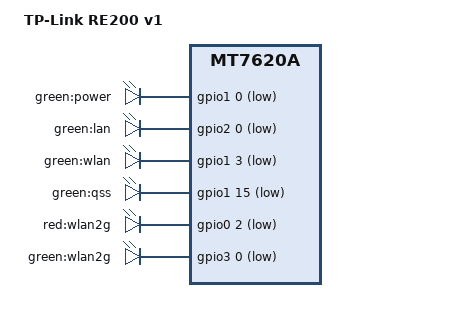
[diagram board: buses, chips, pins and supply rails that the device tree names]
// SPDX-License-Identifier: GPL-2.0-or-later OR MIT

#include "mt7620a_tplink_re2x0-v1.dtsi"

/ {
	compatible = "tplink,re200-v1", "ralink,mt7620a-soc";
	model = "TP-Link RE200 v1";

	aliases {
		led-boot = &led_power;
		led-failsafe = &led_power;
		led-running = &led_power;
		led-upgrade = &led_power;
	};

	leds {
		compatible = "gpio-leds";

		led_power: power {
			label = "green:power";
			gpios = <&gpio1 0 GPIO_ACTIVE_LOW>;
		};

		lan {
			label = "green:lan";
			gpios = <&gpio2 0 GPIO_ACTIVE_LOW>;
		};

		wlan {
			label = "green:wlan";
			gpios = <&gpio1 3 GPIO_ACTIVE_LOW>;
		};

		qss {
			label = "green:qss";
			gpios = <&gpio1 15 GPIO_ACTIVE_LOW>;
		};

		wlan2g_red {
			label = "red:wlan2g";
			gpios = <&gpio0 2 GPIO_ACTIVE_LOW>;
		};

		wlan2g_green {
			label = "green:wlan2g";
			gpios = <&gpio3 0 GPIO_ACTIVE_LOW>;
			linux,default-trigger = "phy1tpt";
		};
	};
};


&state_default {
	gpio {
		groups = "i2c", "uartf", "ephy", "wled", "rgmii1", "spi refclk";
		function = "gpio";
	};
};

&gpio1 {
	status = "okay";
};

&gpio2 {
	status = "okay";
};

&gpio3 {
	status = "okay";
};
